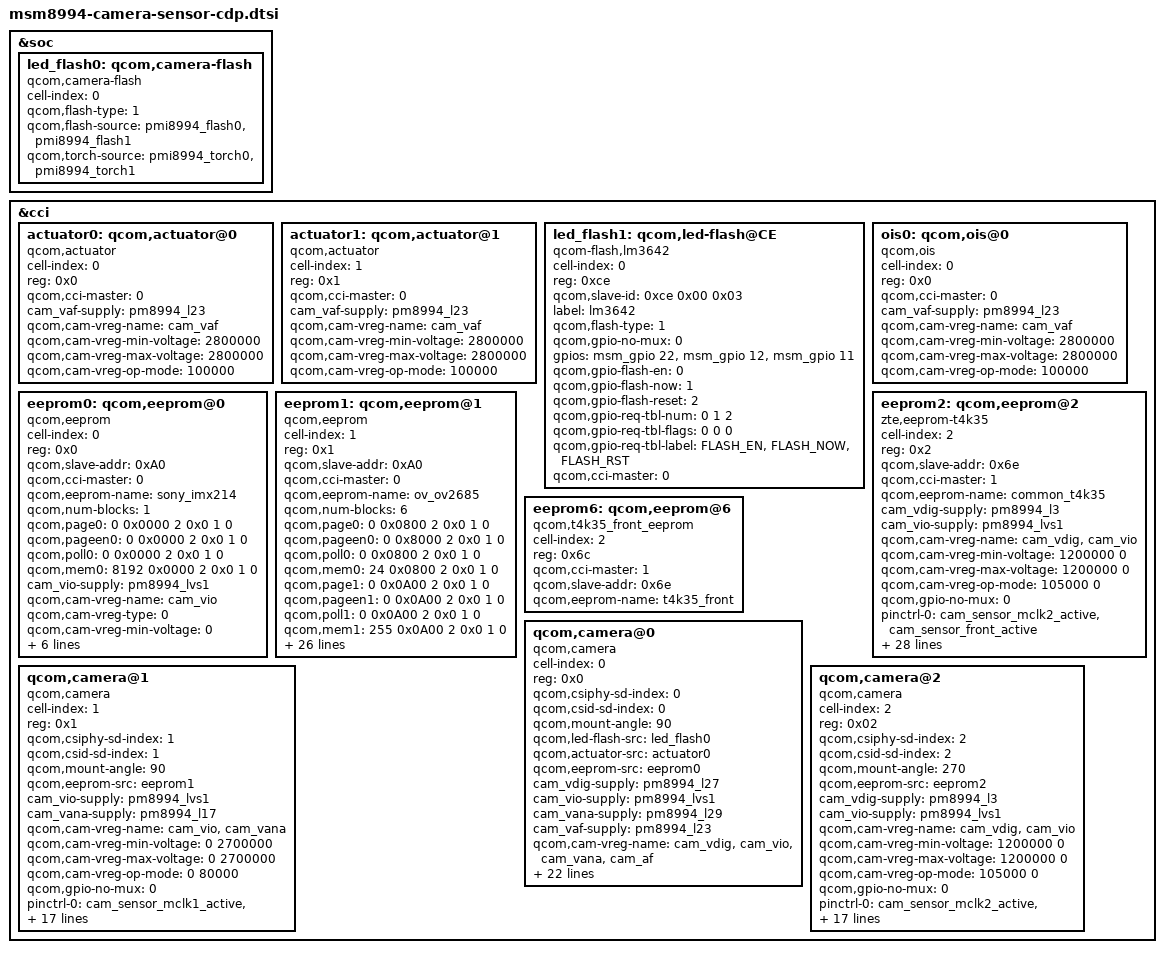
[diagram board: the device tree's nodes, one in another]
/*
 * Copyright (c) 2014, The Linux Foundation. All rights reserved.
 *
 * This program is free software; you can redistribute it and/or modify
 * it under the terms of the GNU General Public License version 2 and
 * only version 2 as published by the Free Software Foundation.
 *
 * This program is distributed in the hope that it will be useful,
 * but WITHOUT ANY WARRANTY; without even the implied warranty of
 * MERCHANTABILITY or FITNESS FOR A PARTICULAR PURPOSE.  See the
 * GNU General Public License for more details.
 */

&soc {

	led_flash0: qcom,camera-flash {
		cell-index = <0>;
		compatible = "qcom,camera-flash";
		qcom,flash-type = <1>;
		qcom,flash-source = <&pmi8994_flash0 &pmi8994_flash1>;
		qcom,torch-source = <&pmi8994_torch0 &pmi8994_torch1>;
	};
	
};

&cci {
	actuator0: qcom,actuator@0 {
		cell-index = <0>;
		reg = <0x0>;
		compatible = "qcom,actuator";
		qcom,cci-master = <0>;
		cam_vaf-supply = <&pm8994_l23>;
		qcom,cam-vreg-name = "cam_vaf";
		qcom,cam-vreg-min-voltage = <2800000>;
		qcom,cam-vreg-max-voltage = <2800000>;
		qcom,cam-vreg-op-mode = <100000>;
	};

	actuator1: qcom,actuator@1 {
		cell-index = <1>;
		reg = <0x1>;
		compatible = "qcom,actuator";
		qcom,cci-master = <0>;
		cam_vaf-supply = <&pm8994_l23>;
		qcom,cam-vreg-name = "cam_vaf";
		qcom,cam-vreg-min-voltage = <2800000>;
		qcom,cam-vreg-max-voltage = <2800000>;
		qcom,cam-vreg-op-mode = <100000>;
	};
  // wangjianping 20150104 added LM3642 flash driver, start

	led_flash1: qcom,led-flash@CE {
		cell-index = <0>;
		reg = <0xce>;
		qcom,slave-id = <0xce 0x00 0x03>;
		compatible = "qcom-flash,lm3642";
		label = "lm3642";
		qcom,flash-type = <1>;
		qcom,gpio-no-mux = <0>;
		gpios = <&msm_gpio 22 0>,   //Strobe 
			    <&msm_gpio 12 0>,   //Torch
			    <&msm_gpio 11 0>;   //Enable
		qcom,gpio-flash-en = <0>;
		qcom,gpio-flash-now = <1>;
		qcom,gpio-flash-reset = <2>;
		qcom,gpio-req-tbl-num = <0 1 2>;
		qcom,gpio-req-tbl-flags = <0 0 0>;
        qcom,gpio-req-tbl-label = "FLASH_EN",
			                      "FLASH_NOW",
			                      "FLASH_RST";
		qcom,cci-master = <0>;
	};
  //wangjianping 20150104 added LM3642 flash driver, end

	ois0: qcom,ois@0 {
		cell-index = <0>;
		reg = <0x0>;
		compatible = "qcom,ois";
		qcom,cci-master = <0>;
		cam_vaf-supply = <&pm8994_l23>;
		qcom,cam-vreg-name = "cam_vaf";
		qcom,cam-vreg-min-voltage = <2800000>;
		qcom,cam-vreg-max-voltage = <2800000>;
		qcom,cam-vreg-op-mode = <100000>;
	};
/*
- qcom,num-blocks : should specify the total block number that eeprom contains,
    every block should contains page poll and mem.
- qcom,page%d : number %d page size, start address, address type, data,
    data type, delay in ms. size 0 stand for non-paged.
    - address type : 1 byte, 2 word.
    - data type : 1 byte, 2 word.
- qcom,poll%d : number %d poll size, poll reg address, address type, data,
    data type, delay in ms. size 0 stand for not used.
    - address type : 1 byte, 2 word.
    - data type : 1 byte, 2 word.
- qcom,mem%d : number %d memory size, start address, address type, data,
    data type, delay in ms. size 0 stand for not used.
    - address type : 1 byte, 2 word.
    - data type : 1 byte, 2 word.
*/

eeprom0: qcom,eeprom@0 {
		compatible = "qcom,eeprom";
		cell-index = <0>;
		reg = <0x0>;
		qcom,slave-addr = <0xA0>;
		qcom,cci-master = <0>;
		qcom,eeprom-name = "sony_imx214";
		qcom,num-blocks = <1>;

		qcom,page0   = <0 0x0000 2 0x0 1 0>;
		qcom,pageen0 = <0 0x0000 2 0x0 1 0>;
		qcom,poll0   = <0 0x0000 2 0x0 1 0>;
		qcom,mem0    = <8192 0x0000 2 0x0 1 0>;

		cam_vio-supply = <&pm8994_lvs1>;
		qcom,cam-vreg-name = "cam_vio";
		qcom,cam-vreg-type = <0>;
		qcom,cam-vreg-min-voltage = <0>;
		qcom,cam-vreg-max-voltage = <0>;
		qcom,cam-vreg-op-mode = <0>;
		qcom,cam-power-seq-type = "sensor_vreg";
		qcom,cam-power-seq-val = "cam_vio";
		qcom,cam-power-seq-cfg-val = <1>;
		qcom,cam-power-seq-delay = <1>;
		status = "ok";
	};
eeprom1: qcom,eeprom@1 {
		compatible = "qcom,eeprom";
		cell-index = <1>;
		reg = <0x1>;
		qcom,slave-addr = <0xA0>;
		qcom,cci-master = <0>;
		qcom,eeprom-name = "ov_ov2685";
		qcom,num-blocks = <6>;

		qcom,page0   = <0 0x0800 2 0x0 1 0>;
		qcom,pageen0 = <0 0x8000 2 0x0 1 0>;
		qcom,poll0   = <0 0x0800 2 0x0 1 0>;
		qcom,mem0    = <24 0x0800 2 0x0 1 0>;

		qcom,page1   = <0 0x0A00 2 0x0 1 0>;
		qcom,pageen1 = <0 0x0A00 2 0x0 1 0>;
		qcom,poll1  = <0 0x0A00 2 0x0 1 0>;
		qcom,mem1    = <255 0x0A00 2 0x0 1 0>;

		qcom,page2   = <0 0x0B00 2 0x0 1 0>;
		qcom,pageen2 = <0 0x0B00 2 0x0 1 0>;
		qcom,poll2  = <0 0x0B00 2 0x0 1 0>;
		qcom,mem2    = <255 0x0B00 2 0x0 1 0>;

		qcom,page3   = <0 0x0C00 2 0x0 1 0>;
		qcom,pageen31 = <0 0x0C00 2 0x0 1 0>;
		qcom,poll3  = <0 0x0C00 2 0x0 1 0>;
		qcom,mem3    = <255 0x0C00 2 0x0 1 0>;

		qcom,page4   = <0 0x0D00 2 0x0 1 0>;
		qcom,pageen4 = <0 0x0D00 2 0x0 1 0>;
		qcom,poll4  = <0 0x0D00 2 0x0 1 0>;
		qcom,mem4    = <255 0x0D00 2 0x0 1 0>;

		qcom,page5   = <0 0x0E00 2 0x0 1 0>;
		qcom,pageen5 = <0 0x0E00 2 0x0 1 0>;
		qcom,poll5  = <0 0x0E00 2 0x0 1 0>;
		qcom,mem5    = <85 0x0E00 2 0x0 1 0>;

		cam_vio-supply = <&pm8994_lvs1>;
		qcom,cam-vreg-name = "cam_vio";
		qcom,cam-vreg-type = <0>;
		qcom,cam-vreg-min-voltage = <0>;
		qcom,cam-vreg-max-voltage = <0>;
		qcom,cam-vreg-op-mode = <0>;
		qcom,cam-power-seq-type = "sensor_vreg";
		qcom,cam-power-seq-val = "cam_vio";
		qcom,cam-power-seq-cfg-val = <1>;
		qcom,cam-power-seq-delay = <1>;
		status = "ok";
	};
	eeprom2: qcom,eeprom@2 {
		compatible = "zte,eeprom-t4k35";
		cell-index = <2>;
		reg = <0x2>;
		qcom,slave-addr = <0x6e>;
		qcom,cci-master = <1>;
		qcom,eeprom-name = "common_t4k35";
		
		cam_vdig-supply = <&pm8994_l3>;
    cam_vio-supply = <&pm8994_lvs1>;
    qcom,cam-vreg-name = "cam_vdig", "cam_vio";
    qcom,cam-vreg-min-voltage = <1200000 0>;
    qcom,cam-vreg-max-voltage = <1200000 0>;
    qcom,cam-vreg-op-mode = <105000 0>;
		
		qcom,gpio-no-mux = <0>;
		pinctrl-names = "cam_default", "cam_suspend";
		pinctrl-0 = <&cam_sensor_mclk2_active &cam_sensor_front_active>;
		pinctrl-1 = <&cam_sensor_mclk2_suspend &cam_sensor_front_suspend>;
		
		gpios = <&msm_gpio 15 0>,
    	<&msm_gpio 104 0>,
    	<&msm_gpio 105 0>,
    	<&msm_gpio 57 0>;
    qcom,gpio-reset = <1>;
    qcom,gpio-standby = <2>;
    qcom,gpio-vana = <3>;
    qcom,gpio-req-tbl-num = <0 1 2 3>;
    qcom,gpio-req-tbl-flags = <1 0 0 0>;
    qcom,gpio-req-tbl-label = "CAMIF_MCLK2",
                              "CAM_RESET2",
                              "CAM_STANDBY2",
                              "CAM_AVDD2";
    qcom,cam-power-seq-type =
                "sensor_gpio",//reset down
								"sensor_gpio",//standby down
								"sensor_vreg",//iovdd
								"sensor_gpio",//avdd down
								"sensor_gpio",//avdd up
								"sensor_vreg",//dvdd
								"sensor_clk",//clk
								"sensor_gpio",//standby up
								"sensor_gpio";//reset up
					  
		qcom,cam-power-seq-val = 
		            "sensor_gpio_reset",
								"sensor_gpio_standby",
								"cam_vio",
								"sensor_gpio_vana",
								"sensor_gpio_vana",
								"cam_vdig",
								"sensor_cam_mclk",
								"sensor_gpio_reset",
								"sensor_gpio_standby";
 
		qcom,cam-power-seq-cfg-val	= < 0 0 0 0 1 0 23880000 1 1>;
		qcom,cam-power-seq-delay		= < 2 2 1 1 1 1 5 10 10>;

		zte,num-blocks = <2>;
		zte,mem0    = <20	 0 2 0x0 1 0>;	//id and golden data
		zte,mem1    = <62	 0 2 0x0 1 0>;  //lsc and awb
		//zte,mem2    = <6	 0 2 0x0 1 0>;  //af
		
		clocks = <&clock_mmss clk_mclk2_clk_src>,
			<&clock_mmss clk_camss_mclk2_clk>;
		clock-names = "cam_src_clk", "cam_clk";
		status = "ok";		
	};
	
	eeprom6: qcom,eeprom@6
	{
		cell-index = <2>;
		reg = <0x6c>;
		compatible = "qcom,t4k35_front_eeprom";
		qcom,cci-master = <1>;
		qcom,slave-addr = <0x6e>;
		qcom,eeprom-name = "t4k35_front";
	};
//imx214
	qcom,camera@0 {
		cell-index = <0>;
		compatible = "qcom,camera";
		reg = <0x0>;
		qcom,csiphy-sd-index = <0>;
		qcom,csid-sd-index = <0>;
		qcom,mount-angle = <90>;
		qcom,led-flash-src = <&led_flash0>;
    qcom,actuator-src = <&actuator0>;
    qcom,eeprom-src = <&eeprom0>;

		cam_vdig-supply = <&pm8994_l27>;
		cam_vio-supply = <&pm8994_lvs1>;
		cam_vana-supply = <&pm8994_l29>;
		cam_vaf-supply = <&pm8994_l23>;
		qcom,cam-vreg-name = "cam_vdig", "cam_vio", "cam_vana","cam_af";
		qcom,cam-vreg-min-voltage = <1050000 0 2800000 2800000>;
		qcom,cam-vreg-max-voltage = <1050000 0 2800000 2800000>;
		qcom,cam-vreg-op-mode = <105000 0 80000 100000>;
		
		qcom,gpio-no-mux = <0>;
		pinctrl-names = "cam_default", "cam_suspend";
		pinctrl-0 = <&cam_sensor_mclk0_active &cam_sensor_rear_active>;
		pinctrl-1 = <&cam_sensor_mclk0_suspend &cam_sensor_rear_suspend>;
		gpios = <&msm_gpio 13 0>,
			<&msm_gpio 92 0>,
			<&msm_gpio 91 0>;
		qcom,gpio-reset = <1>;
		qcom,gpio-standby = <2>;
		qcom,gpio-req-tbl-num = <0 1 2>;
		qcom,gpio-req-tbl-flags = <1 0 0>;
		qcom,gpio-req-tbl-label = "CAMIF_MCLK0",
					  "CAM_RESET0",
					  "CAM_STANDBY0";
		qcom,sensor-position = <0>;
		qcom,sensor-mode = <0>;
		qcom,cci-master = <0>;
		status = "ok";
		clocks = <&clock_mmss clk_mclk0_clk_src>,
				<&clock_mmss clk_camss_mclk0_clk>;
		clock-names = "cam_src_clk", "cam_clk";
	};
//ov2685 yuv
/*
	qcom,camera@78 {
		compatible = "qcom,ov2685";
		reg = <0x78 0x0>;
		qcom,slave-id = <0x78 0x300a 0x2685>;
		qcom,csiphy-sd-index = <1>;
		qcom,csid-sd-index = <1>;
		qcom,mount-angle = <90>;
		qcom,sensor-name = "ov2685";
		
    cam_vio-supply = <&pm8994_lvs1>;
		cam_vana-supply = <&pm8994_l17>;
		qcom,cam-vreg-name ="cam_vio","cam_vana";
		qcom,cam-vreg-min-voltage = <0 2700000>;
		qcom,cam-vreg-max-voltage = <0 2700000>;
		qcom,cam-vreg-op-mode = <0 80000>;
		
		pinctrl-names = "cam_default", "cam_suspend";
		pinctrl-0 = <&cam_sensor_mclk1_active &cam_sensor_rear2_active>;
		pinctrl-1 = <&cam_sensor_mclk1_suspend &cam_sensor_rear2_suspend>;
		
		gpios = <&msm_gpio 14 0>,
			<&msm_gpio 63 0>,
			<&msm_gpio 59 0>,
			<&msm_gpio 69 0>;
		qcom,gpio-reset = <1>;
		qcom,gpio-standby = <2>;
    qcom,gpio-vdig = <3>;
		qcom,gpio-req-tbl-num = <0 1 2 3>;
		qcom,gpio-req-tbl-flags = <1 0 0 0>;
		qcom,gpio-req-tbl-label = "CAMIF_MCLK1",
					  "CAM_RESET1",
					  "CAM_STANDBY1",
					  "CAM_DVDD1";
    
		qcom,csi-lane-assign = <0x4320>;
		qcom,csi-lane-mask = <0x3>;
		qcom,sensor-position = <0>;
		qcom,sensor-mode = <0>;
		qcom,cci-master = <1>;
		status = "ok";
		clocks = <&clock_mmss clk_mclk1_clk_src>,
			<&clock_mmss clk_camss_mclk1_clk>;
		clock-names = "cam_src_clk", "cam_clk";
	};
*/
//ov2685 raw
qcom,camera@1 {
		cell-index = <1>;
		compatible = "qcom,camera";
		reg = <0x1>;
		qcom,csiphy-sd-index = <1>;
		qcom,csid-sd-index = <1>;
		qcom,mount-angle = <90>;
		qcom,eeprom-src = <&eeprom1>;
		
		cam_vio-supply = <&pm8994_lvs1>;
		cam_vana-supply = <&pm8994_l17>;
		qcom,cam-vreg-name ="cam_vio","cam_vana";
		qcom,cam-vreg-min-voltage = <0 2700000>;
		qcom,cam-vreg-max-voltage = <0 2700000>;
		qcom,cam-vreg-op-mode = <0 80000>;
		
		qcom,gpio-no-mux = <0>;
		pinctrl-names = "cam_default", "cam_suspend";
		pinctrl-0 = <&cam_sensor_mclk1_active &cam_sensor_rear2_active>;
		pinctrl-1 = <&cam_sensor_mclk1_suspend &cam_sensor_rear2_suspend>;
		
		gpios = <&msm_gpio 14 0>,
			<&msm_gpio 63 0>,
			<&msm_gpio 59 0>,
			<&msm_gpio 69 0>;
		qcom,gpio-reset = <1>;
		qcom,gpio-standby = <2>;
    qcom,gpio-vdig = <3>;
		qcom,gpio-req-tbl-num = <0 1 2 3>;
		qcom,gpio-req-tbl-flags = <1 0 0 0>;
		qcom,gpio-req-tbl-label = "CAMIF_MCLK1",
					  "CAM_RESET1",
					  "CAM_STANDBY1",
					  "CAM_DVDD1";

		qcom,sensor-position = <0>;
		qcom,sensor-mode = <0>;
		qcom,cci-master = <1>;
		status = "ok";
		clocks = <&clock_mmss clk_mclk1_clk_src>,
			<&clock_mmss clk_camss_mclk1_clk>;
		clock-names = "cam_src_clk", "cam_clk";
	};

qcom,camera@2 {
    cell-index = <2>;
    compatible = "qcom,camera";
    reg = <0x02>;
    qcom,csiphy-sd-index = <2>;
    qcom,csid-sd-index = <2>;
    qcom,mount-angle = <270>;
    qcom,eeprom-src = <&eeprom2>;
    
    cam_vdig-supply = <&pm8994_l3>;
    cam_vio-supply = <&pm8994_lvs1>;
    qcom,cam-vreg-name = "cam_vdig", "cam_vio";
    qcom,cam-vreg-min-voltage = <1200000 0>;
    qcom,cam-vreg-max-voltage = <1200000 0>;
    qcom,cam-vreg-op-mode = <105000 0>;

    qcom,gpio-no-mux = <0>;
    pinctrl-names = "cam_default", "cam_suspend";
    pinctrl-0 = <&cam_sensor_mclk2_active &cam_sensor_front_active>;
    pinctrl-1 = <&cam_sensor_mclk2_suspend &cam_sensor_front_suspend>;

    gpios = <&msm_gpio 15 0>,
    	<&msm_gpio 104 0>,
    	<&msm_gpio 105 0>,
    	<&msm_gpio 57 0>;
    qcom,gpio-reset = <1>;
    qcom,gpio-standby = <2>;
    qcom,gpio-vana = <3>;
    qcom,gpio-req-tbl-num = <0 1 2 3>;
    qcom,gpio-req-tbl-flags = <1 0 0 0>;
    qcom,gpio-req-tbl-label = "CAMIF_MCLK2",
                              "CAM_RESET2",
                              "CAM_STANDBY2",
                              "CAM_AVDD2";

    qcom,sensor-position = <1>;
    qcom,sensor-mode = <0>;
    qcom,cci-master = <1>;
    status = "ok";
    clocks = <&clock_mmss clk_mclk2_clk_src>,<&clock_mmss clk_camss_mclk2_clk>;
    clock-names = "cam_src_clk", "cam_clk";
	};
};
